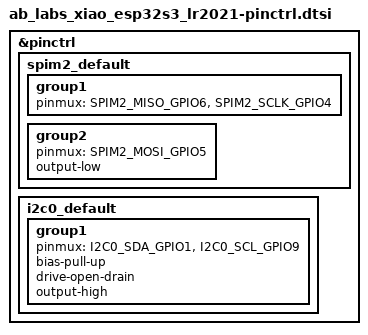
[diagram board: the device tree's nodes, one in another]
/*
 * AB Labs XIAO ESP32-S3 + Wio-LR2021 carrier — pin control
 * SPDX-License-Identifier: MIT
 *
 * MeshCore variants/ab_xiao_nrf52_lr2021 wiring on the ESP32-S3 header map:
 * - SPI2 (LR2021): SCK=GPIO4, MOSI=GPIO5, MISO=GPIO6 (D3-D5)
 * - I2C0: SDA=GPIO1, SCL=GPIO9 (D0, D10)
 * UART0 (GPIO43/44) is not used: D6 is the radio RESET and D7 is DIO7.
 */

#include <zephyr/dt-bindings/pinctrl/esp32s3-pinctrl.h>

&pinctrl {
	spim2_default: spim2_default {
		group1 {
			pinmux = <SPIM2_MISO_GPIO6>,
				 <SPIM2_SCLK_GPIO4>;
		};

		group2 {
			pinmux = <SPIM2_MOSI_GPIO5>;
			output-low;
		};
	};

	i2c0_default: i2c0_default {
		group1 {
			pinmux = <I2C0_SDA_GPIO1>,
				 <I2C0_SCL_GPIO9>;
			bias-pull-up;
			drive-open-drain;
			output-high;
		};
	};
};
